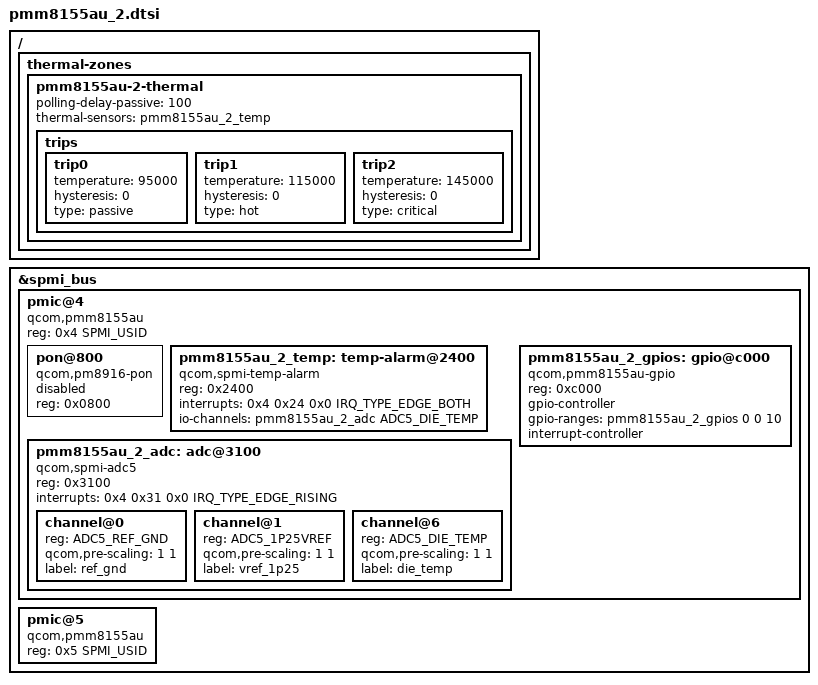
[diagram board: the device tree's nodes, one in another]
// SPDX-License-Identifier: BSD-3-Clause
/*
 * Copyright (c) 2021, Linaro Limited
 */

#include <dt-bindings/input/input.h>
#include <dt-bindings/interrupt-controller/irq.h>
#include <dt-bindings/spmi/spmi.h>

/ {
	thermal-zones {
		pmm8155au-2-thermal {
			polling-delay-passive = <100>;

			thermal-sensors = <&pmm8155au_2_temp>;

			trips {
				trip0 {
					temperature = <95000>;
					hysteresis = <0>;
					type = "passive";
				};

				trip1 {
					temperature = <115000>;
					hysteresis = <0>;
					type = "hot";
				};

				trip2 {
					temperature = <145000>;
					hysteresis = <0>;
					type = "critical";
				};
			};
		};
	};
};

&spmi_bus {
	pmic@4 {
		compatible = "qcom,pmm8155au", "qcom,spmi-pmic";
		reg = <0x4 SPMI_USID>;
		#address-cells = <1>;
		#size-cells = <0>;

		pon@800 {
			compatible = "qcom,pm8916-pon";
			reg = <0x0800>;

			status = "disabled";
		};

		pmm8155au_2_temp: temp-alarm@2400 {
			compatible = "qcom,spmi-temp-alarm";
			reg = <0x2400>;
			interrupts = <0x4 0x24 0x0 IRQ_TYPE_EDGE_BOTH>;
			io-channels = <&pmm8155au_2_adc ADC5_DIE_TEMP>;
			io-channel-names = "thermal";
			#thermal-sensor-cells = <0>;
		};

		pmm8155au_2_adc: adc@3100 {
			compatible = "qcom,spmi-adc5";
			reg = <0x3100>;
			#address-cells = <1>;
			#size-cells = <0>;
			#io-channel-cells = <1>;
			interrupts = <0x4 0x31 0x0 IRQ_TYPE_EDGE_RISING>;

			channel@0 {
				reg = <ADC5_REF_GND>;
				qcom,pre-scaling = <1 1>;
				label = "ref_gnd";
			};

			channel@1 {
				reg = <ADC5_1P25VREF>;
				qcom,pre-scaling = <1 1>;
				label = "vref_1p25";
			};

			channel@6 {
				reg = <ADC5_DIE_TEMP>;
				qcom,pre-scaling = <1 1>;
				label = "die_temp";
			};
		};

		pmm8155au_2_gpios: gpio@c000 {
			compatible = "qcom,pmm8155au-gpio", "qcom,spmi-gpio";
			reg = <0xc000>;
			gpio-controller;
			#gpio-cells = <2>;
			gpio-ranges = <&pmm8155au_2_gpios 0 0 10>;
			interrupt-controller;
			#interrupt-cells = <2>;
		};
	};

	pmic@5 {
		compatible = "qcom,pmm8155au", "qcom,spmi-pmic";
		reg = <0x5 SPMI_USID>;
		#address-cells = <1>;
		#size-cells = <0>;
	};
};
